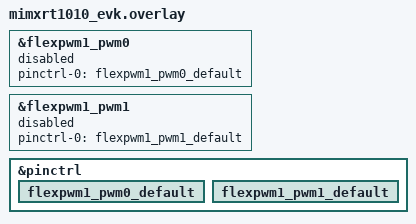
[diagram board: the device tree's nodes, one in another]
/*
 * Copyright (c) 2023 TiaC Systems
 * SPDX-License-Identifier: Apache-2.0
 */

/*
 * On NXP MIMXRT1010-EVK pin D0 (RX) and D1 (TX) will be shared with the
 * on-board FreeLink ISP module (ARM DAPLink CMSIS-DAP / Segger JLink).
 */

#include "arduino_to_grove_if.dtsi"

/*
 * On NXP MIMXRT1010-EVK following pins can be used as PWM outputs:
 *
 *   Grove pin   port         unit   channel   Arduino UNO R3 requirements
 *
 *         D0    GPIO_09                       RX   / GPIO
 *         D1    GPIO_10                       TX   / GPIO
 *   (D10) D2    GPIO_AD_05                    INT0 / GPIO
 *   (D13) D3    GPIO_AD_06   (not possible)   INT1 / GPIO with PWM support
 * (Codec) D4    GPIO_08                       (R800) GPIO
 *   (D18) D5    GPIO_01      (not possible)   (R793) GPIO with PWM support
 *    (A4) D6    GPIO_AD_01   (not possible)          GPIO with PWM support
 *    (A5) D7    GPIO_AD_02                           GPIO
 *         D8    GPIO_SD_02   PWM1   A0               GPIO
 *         D9    GPIO_03      PWM1   B1        (R795) GPIO with PWM support
 * (Flash) D10   GPIO_AD_05                    SS   / GPIO with PWM support
 * (Flash) D11   GPIO_AD_04   (not possible)   MOSI / GPIO with PWM support
 * (Flash) D12   GPIO_AD_03                    MISO / GPIO
 * (Flash) D13   GPIO_AD_06                    SCK  / GPIO
 * (Codec) D18   GPIO_01                       SDA  / GPIO
 *         D19   GPIO_02                       SCL  / GPIO
 */

&flexpwm1_pwm0 {
	status = "disabled";
	pinctrl-0 = <&flexpwm1_pwm0_default>;
	pinctrl-names = "default";
};

#undef GROVE_PWM_D8_ENABLE
#define GROVE_PWM_D8_ENABLE						\
	&flexpwm1_pwm0 {						\
		status = "okay";					\
	};

#undef GROVE_PWM_D8_PINCTRL
#define GROVE_PWM_D8_PINCTRL						\
	&flexpwm1_pwm0_default {					\
		group8 {						\
			pinmux = <&iomuxc_gpio_sd_02_flexpwm1_pwm0_a>;	\
			drive-strength = "r0-4";			\
			bias-pull-up;					\
			bias-pull-up-value = "47k";			\
			slew-rate = "slow";				\
			nxp,speed = "50-mhz";				\
		};							\
	};

&flexpwm1_pwm1 {
	status = "disabled";
	pinctrl-0 = <&flexpwm1_pwm1_default>;
	pinctrl-names = "default";
};

#undef GROVE_PWM_D9_ENABLE
#define GROVE_PWM_D9_ENABLE						\
	&flexpwm1_pwm1 {						\
		status = "okay";					\
	};

#undef GROVE_PWM_D9_PINCTRL
#define GROVE_PWM_D9_PINCTRL						\
	&flexpwm1_pwm1_default {					\
		group9 {						\
			pinmux = <&iomuxc_gpio_03_flexpwm1_pwm1_b>;	\
			drive-strength = "r0-4";			\
			bias-pull-up;					\
			bias-pull-up-value = "47k";			\
			slew-rate = "slow";				\
			nxp,speed = "50-mhz";				\
		};							\
	};

&pinctrl {
	flexpwm1_pwm0_default: flexpwm1_pwm0_default {};
	flexpwm1_pwm1_default: flexpwm1_pwm1_default {};
};
